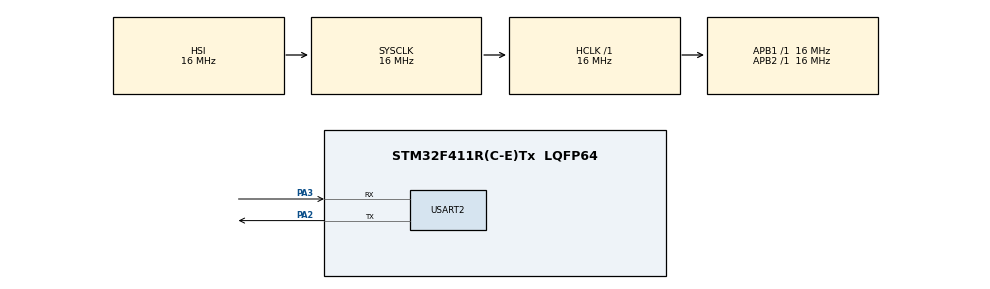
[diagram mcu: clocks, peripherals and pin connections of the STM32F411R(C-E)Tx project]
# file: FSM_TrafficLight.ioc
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Dma.Request0=USART2_RX
Dma.USART2_RX.0.Direction=DMA_PERIPH_TO_MEMORY
Dma.USART2_RX.0.FIFOMode=DMA_FIFOMODE_DISABLE
Dma.USART2_RX.0.Instance=DMA1_Stream5
Dma.USART2_RX.0.MemDataAlignment=DMA_MDATAALIGN_BYTE
Dma.USART2_RX.0.MemInc=DMA_MINC_ENABLE
Dma.USART2_RX.0.Mode=DMA_NORMAL
Dma.USART2_RX.0.PeriphDataAlignment=DMA_PDATAALIGN_BYTE
Dma.USART2_RX.0.PeriphInc=DMA_PINC_DISABLE
Dma.USART2_RX.0.Priority=DMA_PRIORITY_LOW
FREERTOS.Tasks01=Intersection_4,40,256,StartIntersection_4,Default,NULL,Dynamic,NULL,NULL
Mcu.Family=STM32F4
Mcu.Name=STM32F411R(C-E)Tx
Mcu.Package=LQFP64
NVIC.DMA1_Stream5_IRQn=true\:5\:0\:false\:false\:true\:true\:false\:true\:true
NVIC.PriorityGroup=NVIC_PRIORITYGROUP_4
NVIC.TIM1_UP_TIM10_IRQn=true\:15\:0\:false\:false\:true\:false\:false\:true\:true
NVIC.TimeBase=TIM1_UP_TIM10_IRQn
NVIC.TimeBaseIP=TIM1
NVIC.USART2_IRQn=true\:5\:0\:false\:false\:true\:true\:true\:true\:true
PA2.Mode=Asynchronous
PA2.Signal=USART2_TX
PA3.Mode=Asynchronous
PA3.Signal=USART2_RX
ProjectManager.HeapSize=0x200
ProjectManager.StackSize=0x400
ProjectManager.TargetToolchain=STM32CubeIDE
RCC.AHBFreq_Value=16000000
RCC.APB1Freq_Value=16000000
RCC.APB2Freq_Value=16000000
RCC.CortexFreq_Value=16000000
RCC.HSE_VALUE=25000000
RCC.HSI_VALUE=16000000
RCC.LSE_VALUE=32768
RCC.SYSCLKFreq_VALUE=16000000
RCC.VCOOutputFreq_Value=192000000
USART2.VirtualMode=VM_ASYNC
VP_FREERTOS_VS_CMSIS_V2.Mode=CMSIS_V2
VP_SYS_VS_tim1.Mode=TIM1
board=custom

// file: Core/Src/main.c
/* USER CODE BEGIN Header */
/**
  ******************************************************************************
  * @file           : main.c
  * @brief          : Main program body
  ******************************************************************************
  * @attention
  *
  * Copyright (c) 2026 STMicroelectronics.
  * All rights reserved.
  *
  * This software is licensed under terms that can be found in the LICENSE file
  * in the root directory of this software component.
  * If no LICENSE file comes with this software, it is provided AS-IS.
  *
  ******************************************************************************
  */
/* USER CODE END Header */
#include "main.h"
#include "cmsis_os.h"
#include "dma.h"
#include "usart.h"
#include "gpio.h"

/* USER CODE BEGIN Includes */
#include "intersections.h"
/* USER CODE END Includes */

void SystemClock_Config(void);
void MX_FREERTOS_Init(void);

int main(void)
{

  /* MCU Configuration--------------------------------------------------------*/

  /* Reset of all peripherals, Initializes the Flash interface and the Systick. */
  HAL_Init();

  /* Configure the system clock */
  SystemClock_Config();

  /* Initialize all configured peripherals */
  MX_GPIO_Init();
  MX_DMA_Init();
  MX_USART2_UART_Init();

  /* Init scheduler */
  osKernelInitialize();  /* Call init function for freertos objects (in freertos.c) */
//  MX_FREERTOS_Init();
  MyTrafficSystem();

  /* Start scheduler */
  osKernelStart();
  /* We should never get here as control is now taken by the scheduler */
  /* Infinite loop */
  while (1)
  {

  }
}

void SystemClock_Config(void)
{
  RCC_OscInitTypeDef RCC_OscInitStruct = {0};
  RCC_ClkInitTypeDef RCC_ClkInitStruct = {0};

  /** Configure the main internal regulator output voltage
  */
  __HAL_RCC_PWR_CLK_ENABLE();
  __HAL_PWR_VOLTAGESCALING_CONFIG(PWR_REGULATOR_VOLTAGE_SCALE1);

  /** Initializes the RCC Oscillators according to the specified parameters
  * in the RCC_OscInitTypeDef structure.
  */
  RCC_OscInitStruct.OscillatorType = RCC_OSCILLATORTYPE_HSI;
  RCC_OscInitStruct.HSIState = RCC_HSI_ON;
  RCC_OscInitStruct.HSICalibrationValue = RCC_HSICALIBRATION_DEFAULT;
  RCC_OscInitStruct.PLL.PLLState = RCC_PLL_NONE;
  if (HAL_RCC_OscConfig(&RCC_OscInitStruct) != HAL_OK)
  {
    Error_Handler();
  }

  /** Initializes the CPU, AHB and APB buses clocks
  */
  RCC_ClkInitStruct.ClockType = RCC_CLOCKTYPE_HCLK|RCC_CLOCKTYPE_SYSCLK
                              |RCC_CLOCKTYPE_PCLK1|RCC_CLOCKTYPE_PCLK2;
  RCC_ClkInitStruct.SYSCLKSource = RCC_SYSCLKSOURCE_HSI;
  RCC_ClkInitStruct.AHBCLKDivider = RCC_SYSCLK_DIV1;
  RCC_ClkInitStruct.APB1CLKDivider = RCC_HCLK_DIV1;
  RCC_ClkInitStruct.APB2CLKDivider = RCC_HCLK_DIV1;

  if (HAL_RCC_ClockConfig(&RCC_ClkInitStruct, FLASH_LATENCY_0) != HAL_OK)
  {
    Error_Handler();
  }
}

void HAL_TIM_PeriodElapsedCallback(TIM_HandleTypeDef *htim)
{
  if (htim->Instance == TIM1) {
    HAL_IncTick();
  }
}

void Error_Handler(void)
{
  __disable_irq();
  while (1)
  {
  }
}

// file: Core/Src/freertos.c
/* USER CODE BEGIN Header */
/**
  ******************************************************************************
  * File Name          : freertos.c
  * Description        : Code for freertos applications
  ******************************************************************************
  * @attention
  *
  * Copyright (c) 2026 STMicroelectronics.
  * All rights reserved.
  *
  * This software is licensed under terms that can be found in the LICENSE file
  * in the root directory of this software component.
  * If no LICENSE file comes with this software, it is provided AS-IS.
  *
  ******************************************************************************
  */
/* USER CODE END Header */

#include "FreeRTOS.h"
#include "task.h"
#include "main.h"
#include "cmsis_os.h"

/* Definitions for Intersection_4 */
osThreadId_t Intersection_4Handle;
const osThreadAttr_t Intersection_4_attributes = {
  .name = "Intersection_4",
  .stack_size = 256 * 4,
  .priority = (osPriority_t) osPriorityHigh,
};

void StartIntersection_4(void *argument);

void MX_FREERTOS_Init(void); /* (MISRA C 2004 rule 8.1) */

void MX_FREERTOS_Init(void) {

  /* Create the thread(s) */
  /* creation of Intersection_4 */
  Intersection_4Handle = osThreadNew(StartIntersection_4, NULL, &Intersection_4_attributes);

}

void StartIntersection_4(void *argument)
{
  for(;;)
  {
    osDelay(1);
  }
}
